# StarFive VisionFive 2 v1.3b register map
File version: 0.1
Registers are 32-bit, read-write, no defined reset value unless marked. A register's access mark holds for its fields unless they carry their own. Offsets are from the block's base; [hi:lo] are bit positions; 'fields as' and 'values as' point back to an identical list.

## starfive_jh7110_stg_syscon_0 — From starfive,jh7110-stg-syscon, peripheral generator
Base 0x10240000
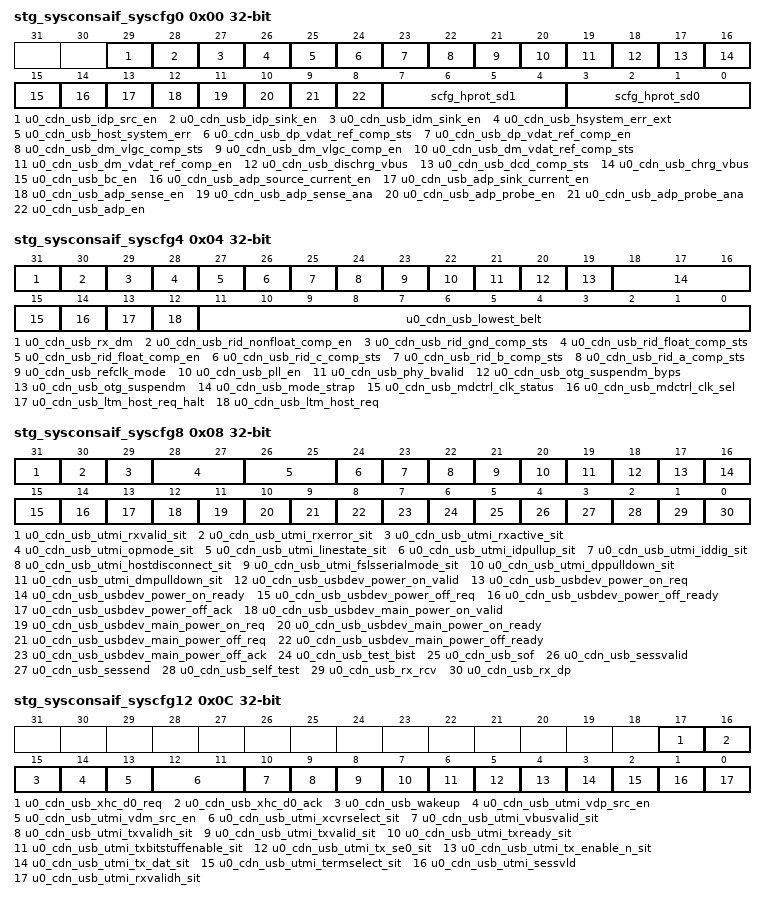
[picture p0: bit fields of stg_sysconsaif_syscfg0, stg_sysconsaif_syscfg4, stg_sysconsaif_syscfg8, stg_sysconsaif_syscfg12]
0x00 stg_sysconsaif_syscfg0
  [29] u0_cdn_usb_idp_src_en ro, [28] u0_cdn_usb_idp_sink_en ro, [27] u0_cdn_usb_idm_sink_en ro, [26] u0_cdn_usb_hsystem_err_ext ro, [25] u0_cdn_usb_host_system_err, [24] u0_cdn_usb_dp_vdat_ref_comp_sts, [23] u0_cdn_usb_dp_vdat_ref_comp_en ro, [22] u0_cdn_usb_dm_vlgc_comp_sts, [21] u0_cdn_usb_dm_vlgc_comp_en ro, [20] u0_cdn_usb_dm_vdat_ref_comp_sts, [19] u0_cdn_usb_dm_vdat_ref_comp_en ro, [18] u0_cdn_usb_dischrg_vbus, [17] u0_cdn_usb_dcd_comp_sts, [16] u0_cdn_usb_chrg_vbus, [15] u0_cdn_usb_bc_en ro, [14] u0_cdn_usb_adp_source_current_en ro, [13] u0_cdn_usb_adp_sink_current_en ro, [12] u0_cdn_usb_adp_sense_en ro, [11] u0_cdn_usb_adp_sense_ana, [10] u0_cdn_usb_adp_probe_en ro, [9] u0_cdn_usb_adp_probe_ana, [8] u0_cdn_usb_adp_en ro, [7:4] scfg_hprot_sd1, [3:0] scfg_hprot_sd0
0x04 stg_sysconsaif_syscfg4
  [31] u0_cdn_usb_rx_dm ro
  [30] u0_cdn_usb_rid_nonfloat_comp_en ro
  [29] u0_cdn_usb_rid_gnd_comp_sts
  [28] u0_cdn_usb_rid_float_comp_sts
  [27] u0_cdn_usb_rid_float_comp_en ro
  [26] u0_cdn_usb_rid_c_comp_sts
  [25] u0_cdn_usb_rid_b_comp_sts
  [24] u0_cdn_usb_rid_a_comp_sts
  [23] u0_cdn_usb_refclk_mode
  [22] u0_cdn_usb_pll_en
  [21] u0_cdn_usb_phy_bvalid ro
  [20] u0_cdn_usb_otg_suspendm_byps
  [19] u0_cdn_usb_otg_suspendm
  [18:16] u0_cdn_usb_mode_strap — Can onlly be changed when pwrup_rst_n is low
  [15] u0_cdn_usb_mdctrl_clk_status ro
  [14] u0_cdn_usb_mdctrl_clk_sel
  [13] u0_cdn_usb_ltm_host_req_halt — LTM interface to software
  [12] u0_cdn_usb_ltm_host_req ro — LTM interface to software
  [11:0] u0_cdn_usb_lowest_belt ro — LTM interface to software
0x08 stg_sysconsaif_syscfg8
  [31] u0_cdn_usb_utmi_rxvalid_sit ro
  [30] u0_cdn_usb_utmi_rxerror_sit ro
  [29] u0_cdn_usb_utmi_rxactive_sit ro
  [28:27] u0_cdn_usb_utmi_opmode_sit
  [26:25] u0_cdn_usb_utmi_linestate_sit ro
  [24] u0_cdn_usb_utmi_idpullup_sit
  [23] u0_cdn_usb_utmi_iddig_sit ro
  [22] u0_cdn_usb_utmi_hostdisconnect_sit ro
  [21] u0_cdn_usb_utmi_fslsserialmode_sit
  [20] u0_cdn_usb_utmi_dppulldown_sit
  [19] u0_cdn_usb_utmi_dmpulldown_sit
  [18] u0_cdn_usb_usbdev_power_on_valid
  [17] u0_cdn_usb_usbdev_power_on_req ro
  [16] u0_cdn_usb_usbdev_power_on_ready ro
  [15] u0_cdn_usb_usbdev_power_off_req
  [14] u0_cdn_usb_usbdev_power_off_ready ro
  [13] u0_cdn_usb_usbdev_power_off_ack ro
  [12] u0_cdn_usb_usbdev_main_power_on_valid
  [11] u0_cdn_usb_usbdev_main_power_on_req ro
  [10] u0_cdn_usb_usbdev_main_power_on_ready ro
  [9] u0_cdn_usb_usbdev_main_power_off_req
  [8] u0_cdn_usb_usbdev_main_power_off_ready ro
  [7] u0_cdn_usb_usbdev_main_power_off_ack ro
  [6] u0_cdn_usb_test_bist ro — For software bist_test
  [5] u0_cdn_usb_sof ro
  [4] u0_cdn_usb_sessvalid ro
  [3] u0_cdn_usb_sessend ro
  [2] u0_cdn_usb_self_test — For software bist_test
  [1] u0_cdn_usb_rx_rcv ro
  [0] u0_cdn_usb_rx_dp ro
0x0C stg_sysconsaif_syscfg12
  [17] u0_cdn_usb_xhc_d0_req, [16] u0_cdn_usb_xhc_d0_ack ro, [15] u0_cdn_usb_wakeup, [14] u0_cdn_usb_utmi_vdp_src_en ro, [13] u0_cdn_usb_utmi_vdm_src_en ro, [12:11] u0_cdn_usb_utmi_xcvrselect_sit, [10] u0_cdn_usb_utmi_vbusvalid_sit ro, [9] u0_cdn_usb_utmi_txvalidh_sit, [8] u0_cdn_usb_utmi_txvalid_sit, [7] u0_cdn_usb_utmi_txready_sit ro, [6] u0_cdn_usb_utmi_txbitstuffenable_sit, [5] u0_cdn_usb_utmi_tx_se0_sit, [4] u0_cdn_usb_utmi_tx_enable_n_sit, [3] u0_cdn_usb_utmi_tx_dat_sit, [2] u0_cdn_usb_utmi_termselect_sit, [1] u0_cdn_usb_utmi_sessvld, [0] u0_cdn_usb_utmi_rxvalidh_sit ro
0x10 stg_sysconsaif_syscfg16
  [31:0] u0_cdn_usb_xhci_debug_bus ro
0x14 stg_sysconsaif_syscfg20
  [30:0] u0_cdn_usb_xhci_debug_link_state ro
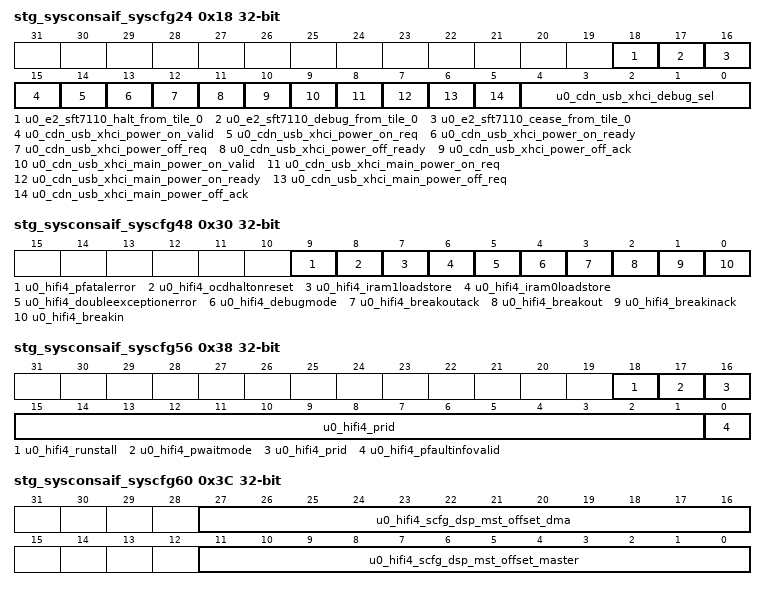
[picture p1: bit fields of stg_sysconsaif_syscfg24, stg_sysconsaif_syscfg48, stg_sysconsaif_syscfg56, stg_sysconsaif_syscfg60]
0x18 stg_sysconsaif_syscfg24
  [18] u0_e2_sft7110_halt_from_tile_0 ro, [17] u0_e2_sft7110_debug_from_tile_0 ro, [16] u0_e2_sft7110_cease_from_tile_0 ro, [15] u0_cdn_usb_xhci_power_on_valid, [14] u0_cdn_usb_xhci_power_on_req ro, [13] u0_cdn_usb_xhci_power_on_ready ro, [12] u0_cdn_usb_xhci_power_off_req, [11] u0_cdn_usb_xhci_power_off_ready ro, [10] u0_cdn_usb_xhci_power_off_ack ro, [9] u0_cdn_usb_xhci_main_power_on_valid, [8] u0_cdn_usb_xhci_main_power_on_req ro, [7] u0_cdn_usb_xhci_main_power_on_ready, [6] u0_cdn_usb_xhci_main_power_off_req ro, [5] u0_cdn_usb_xhci_main_power_off_ack ro, [4:0] u0_cdn_usb_xhci_debug_sel
0x1C stg_sysconsaif_syscfg28
  [31:0] u0_e2_sft7110_nmi_0_rnmi_exception_vector
0x20 stg_sysconsaif_syscfg32
  [31:0] u0_e2_sft7110_nmi_0_rnmi_interrupt_vector
0x24 stg_sysconsaif_syscfg36
  [31:0] u0_e2_sft7110_reset_vector_0
0x28 stg_sysconsaif_syscfg40
  [0] u0_e2_sft7110_wfi_from_tile_0 ro
0x2C stg_sysconsaif_syscfg44
  [31:0] u0_hifi4_altresetvec — Reset Vector Address
0x30 stg_sysconsaif_syscfg48
  [9] u0_hifi4_pfatalerror ro — Fault Handling Signals
  [8] u0_hifi4_ocdhaltonreset — Debug signal
  [7] u0_hifi4_iram1loadstore ro — Indicates that iram1 works
  [6] u0_hifi4_iram0loadstore ro — Indicates that iram0 works
  [5] u0_hifi4_doubleexceptionerror ro — Fault Handling Signals
  [4] u0_hifi4_debugmode ro — Debug signal
  [3] u0_hifi4_breakoutack — Debug signal
  [2] u0_hifi4_breakout ro — Debug signal
  [1] u0_hifi4_breakinack ro — Debug signal
  [0] u0_hifi4_breakin — Debug signal
0x34 stg_sysconsaif_syscfg52
  [31:0] u0_hifi4_pfaultinfo ro — Fault Handling Signals
0x38 stg_sysconsaif_syscfg56
  [18] u0_hifi4_runstall — Run Stall
  [17] u0_hifi4_pwaitmode ro — Wait Mode
  [16:1] u0_hifi4_prid — Module ID
  [0] u0_hifi4_pfaultinfovalid ro — Fault Handling Signals
0x3C stg_sysconsaif_syscfg60
  [27:16] u0_hifi4_scfg_dsp_mst_offset_dma — Indicates the DMA port remap address
  [11:0] u0_hifi4_scfg_dsp_mst_offset_master — Indicates that master port remap address
0x40 stg_sysconsaif_syscfg64
  [31:0] u0_hifi4_scfg_dsp_slv_offset — The value indicates the slave port remap address
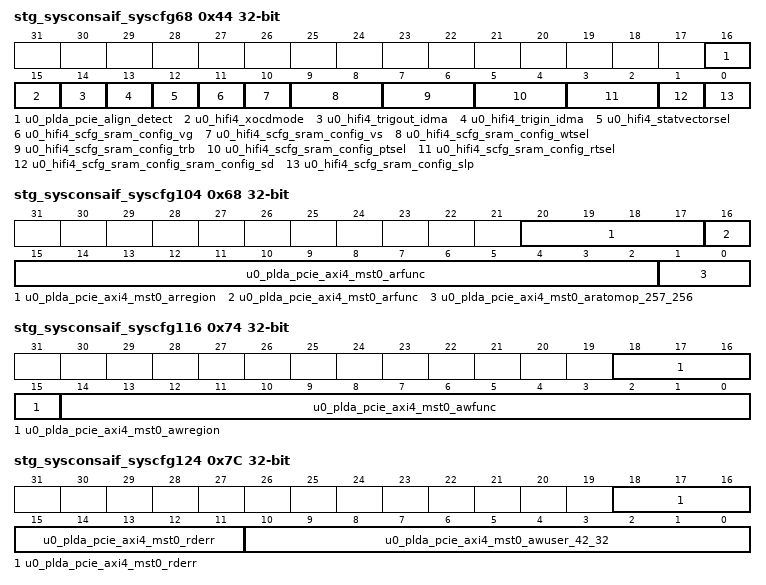
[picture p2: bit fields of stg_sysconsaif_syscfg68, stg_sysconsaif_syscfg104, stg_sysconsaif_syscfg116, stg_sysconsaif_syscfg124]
0x44 stg_sysconsaif_syscfg68
  [16] u0_plda_pcie_align_detect ro
  [15] u0_hifi4_xocdmode ro — Debug signal
  [14] u0_hifi4_trigout_idma ro — DMA port trigger
  [13] u0_hifi4_trigin_idma — DMA port trigger
  [12] u0_hifi4_statvectorsel — When the value is 1, it indicates that the AltResetVec is valid
  [11] u0_hifi4_scfg_sram_config_vg — SRAM/ROM configuration. VG: timing setting for debug purpose, default is 1'b1.
  [10] u0_hifi4_scfg_sram_config_vs — SRAM/ROM configuration. VS: timing setting for debug purpose, default is 1'b1.
  [9:8] u0_hifi4_scfg_sram_config_wtsel — SRAM/ROM configuration. WTSEL: timing setting for debug purpose, default is 2'b01.
  [7:6] u0_hifi4_scfg_sram_config_trb — SRAM/ROM configuration. TRB: timing setting for debug purpose, default is 2'b01.
  [5:4] u0_hifi4_scfg_sram_config_ptsel — SRAM/ROM configuration. PTSEL: timing setting for debug purpose, default is 2'b01.
  [3:2] u0_hifi4_scfg_sram_config_rtsel — SRAM/ROM configuration. RTSEL: timing setting for debug purpose, default is 2'b01.
  [1] u0_hifi4_scfg_sram_config_sram_config_sd — SRAM/ROM configuration. SD: shutdown enable, high active, default is low.
  [0] u0_hifi4_scfg_sram_config_slp — SRAM/ROM configuration. SLP: sleep enable, high active, default is low.
0x48 stg_sysconsaif_syscfg72
  [31:0] u0_plda_pcie_axi4_mst0_aratomop_31_0 ro
0x4C stg_sysconsaif_syscfg76
  [31:0] u0_plda_pcie_axi4_mst0_aratomop_63_32 ro
0x50 stg_sysconsaif_syscfg80
  [31:0] u0_plda_pcie_axi4_mst0_aratomop_95_64 ro
0x54 stg_sysconsaif_syscfg84
  [31:0] u0_plda_pcie_axi4_mst0_aratomop_127_96 ro
0x58 stg_sysconsaif_syscfg88
  [31:0] u0_plda_pcie_axi4_mst0_aratomop_159_128 ro
0x5C stg_sysconsaif_syscfg92
  [31:0] u0_plda_pcie_axi4_mst0_aratomop_191_160 ro
0x60 stg_sysconsaif_syscfg96
  [31:0] u0_plda_pcie_axi4_mst0_aratomop_223_192 ro
0x64 stg_sysconsaif_syscfg100
  [31:0] u0_plda_pcie_axi4_mst0_aratomop_255_224 ro
0x68 stg_sysconsaif_syscfg104
  [20:17] u0_plda_pcie_axi4_mst0_arregion ro, [16:2] u0_plda_pcie_axi4_mst0_arfunc ro, [1:0] u0_plda_pcie_axi4_mst0_aratomop_257_256 ro
0x6C stg_sysconsaif_syscfg108
  [31:0] u0_plda_pcie_axi4_mst0_aruser_31_0 ro
0x70 stg_sysconsaif_syscfg112
  [31:0] u0_plda_pcie_axi4_mst0_aruser_63_32 ro
0x74 stg_sysconsaif_syscfg116
  [18:15] u0_plda_pcie_axi4_mst0_awregion ro, [14:0] u0_plda_pcie_axi4_mst0_awfunc ro
0x78 stg_sysconsaif_syscfg120
  [31:0] u0_plda_pcie_axi4_mst0_a2user_31_0 ro
0x7C stg_sysconsaif_syscfg124
  [18:11] u0_plda_pcie_axi4_mst0_rderr, [10:0] u0_plda_pcie_axi4_mst0_awuser_42_32 ro
0x80 stg_sysconsaif_syscfg128
  [31:0] u0_plda_pcie_axi4_mst0_ruser
0x84 stg_sysconsaif_syscfg132
  [7:0] u0_plda_pcie_axi4_mst0_wderr ro
0x88 stg_sysconsaif_syscfg136
  [31:0] u0_plda_pcie_axi4_slv0_aratomop_31_0
0x8C stg_sysconsaif_syscfg140
  [31:0] u0_plda_pcie_axi4_slv0_aratomop_63_32
0x90 stg_sysconsaif_syscfg144
  [31:0] u0_plda_pcie_axi4_slv0_aratomop_95_64
0x94 stg_sysconsaif_syscfg148
  [31:0] u0_plda_pcie_axi4_slv0_aratomop_127_96
0x98 stg_sysconsaif_syscfg152
  [31:0] u0_plda_pcie_axi4_slv0_aratomop_159_128
0x9C stg_sysconsaif_syscfg156
  [31:0] u0_plda_pcie_axi4_slv0_aratomop_191_160
0xA0 stg_sysconsaif_syscfg160
  [31:0] u0_plda_pcie_axi4_slv0_aratomop_223_192
0xA4 stg_sysconsaif_syscfg164
  [31:0] u0_plda_pcie_axi4_slv0_aratomop_255_224
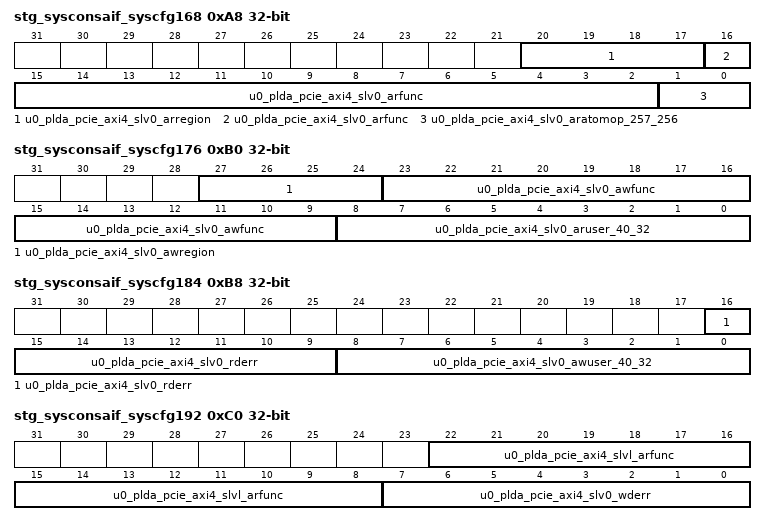
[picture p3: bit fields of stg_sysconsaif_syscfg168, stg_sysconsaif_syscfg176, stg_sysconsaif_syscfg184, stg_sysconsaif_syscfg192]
0xA8 stg_sysconsaif_syscfg168
  [20:17] u0_plda_pcie_axi4_slv0_arregion, [16:2] u0_plda_pcie_axi4_slv0_arfunc, [1:0] u0_plda_pcie_axi4_slv0_aratomop_257_256
0xAC stg_sysconsaif_syscfg172
  [31:0] u0_plda_pcie_axi4_slv0_aruser_31_0
0xB0 stg_sysconsaif_syscfg176
  [27:24] u0_plda_pcie_axi4_slv0_awregion, [23:9] u0_plda_pcie_axi4_slv0_awfunc, [8:0] u0_plda_pcie_axi4_slv0_aruser_40_32
0xB4 stg_sysconsaif_syscfg180
  [31:0] u0_plda_pcie_axi4_slv0_awuser_31_0
0xB8 stg_sysconsaif_syscfg184
  [16:9] u0_plda_pcie_axi4_slv0_rderr ro, [8:0] u0_plda_pcie_axi4_slv0_awuser_40_32
0xBC stg_sysconsaif_syscfg188
  [31:0] u0_plda_pcie_axi4_slv0_ruser ro
0xC0 stg_sysconsaif_syscfg192
  [22:8] u0_plda_pcie_axi4_slvl_arfunc ro, [7:0] u0_plda_pcie_axi4_slv0_wderr
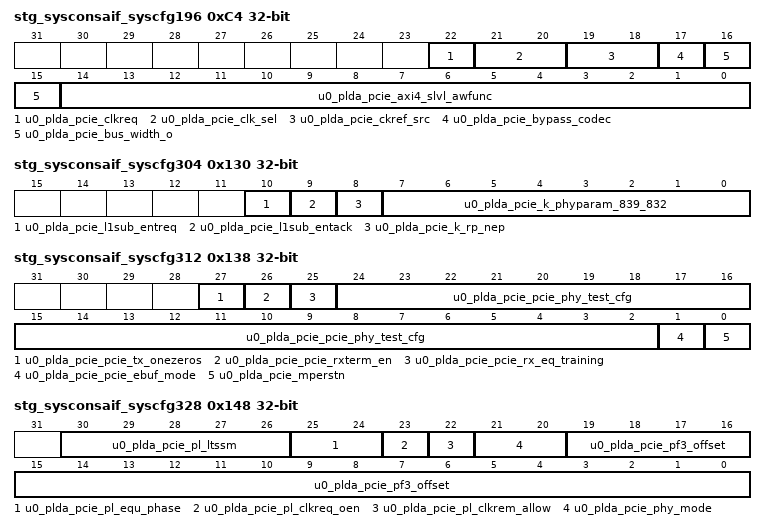
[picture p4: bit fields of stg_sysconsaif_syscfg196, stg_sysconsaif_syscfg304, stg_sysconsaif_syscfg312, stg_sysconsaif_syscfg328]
0xC4 stg_sysconsaif_syscfg196
  [22] u0_plda_pcie_clkreq, [21:20] u0_plda_pcie_clk_sel, [19:18] u0_plda_pcie_ckref_src, [17] u0_plda_pcie_bypass_codec, [16:15] u0_plda_pcie_bus_width_o ro, [14:0] u0_plda_pcie_axi4_slvl_awfunc
0xC8 stg_sysconsaif_syscfg200
  [31:0] u0_plda_pcie_k_phyparam_31_0
0xCC stg_sysconsaif_syscfg204
  [31:0] u0_plda_pcie_k_phyparam_63_32
0xD0 stg_sysconsaif_syscfg208
  [31:0] u0_plda_pcie_k_phyparam_95_64
0xD4 stg_sysconsaif_syscfg212
  [31:0] u0_plda_pcie_k_phyparam_127_96
0xD8 stg_sysconsaif_syscfg216
  [31:0] u0_plda_pcie_k_phyparam_159_128
0xDC stg_sysconsaif_syscfg220
  [31:0] u0_plda_pcie_k_phyparam_191_160
0xE0 stg_sysconsaif_syscfg224
  [31:0] u0_plda_pcie_k_phyparam_223_192
0xE4 stg_sysconsaif_syscfg228
  [31:0] u0_plda_pcie_k_phyparam_255_224
0xE8 stg_sysconsaif_syscfg232
  [31:0] u0_plda_pcie_k_phyparam_287_256
0xEC stg_sysconsaif_syscfg236
  [31:0] u0_plda_pcie_k_phyparam_319_288
0xF0 stg_sysconsaif_syscfg240
  [31:0] u0_plda_pcie_k_phyparam_351_320
0xF4 stg_sysconsaif_syscfg244
  [31:0] u0_plda_pcie_k_phyparam_383_352
0xF8 stg_sysconsaif_syscfg248
  [31:0] u0_plda_pcie_k_phyparam_415_384
0xFC stg_sysconsaif_syscfg252
  [31:0] u0_plda_pcie_k_phyparam_447_416
0x100 stg_sysconsaif_syscfg256
  [31:0] u0_plda_pcie_k_phyparam_479_448
0x104 stg_sysconsaif_syscfg260
  [31:0] u0_plda_pcie_k_phyparam_511_480
0x108 stg_sysconsaif_syscfg264
  [31:0] u0_plda_pcie_k_phyparam_543_512
0x10C stg_sysconsaif_syscfg268
  [31:0] u0_plda_pcie_k_phyparam_575_544
0x110 stg_sysconsaif_syscfg272
  [31:0] u0_plda_pcie_k_phyparam_607_576
0x114 stg_sysconsaif_syscfg276
  [31:0] u0_plda_pcie_k_phyparam_639_608
0x118 stg_sysconsaif_syscfg280
  [31:0] u0_plda_pcie_k_phyparam_671_640
0x11C stg_sysconsaif_syscfg284
  [31:0] u0_plda_pcie_k_phyparam_703_672
0x120 stg_sysconsaif_syscfg288
  [31:0] u0_plda_pcie_k_phyparam_735_704
0x124 stg_sysconsaif_syscfg292
  [31:0] u0_plda_pcie_k_phyparam_767_736
0x128 stg_sysconsaif_syscfg296
  [31:0] u0_plda_pcie_k_phyparam_799_768
0x12C stg_sysconsaif_syscfg300
  [31:0] u0_plda_pcie_k_phyparam_831_800
0x130 stg_sysconsaif_syscfg304
  [10] u0_plda_pcie_l1sub_entreq, [9] u0_plda_pcie_l1sub_entack ro, [8] u0_plda_pcie_k_rp_nep, [7:0] u0_plda_pcie_k_phyparam_839_832
0x134 stg_sysconsaif_syscfg308
  [31:0] u0_plda_pcie_local_interrupt_in
0x138 stg_sysconsaif_syscfg312
  [27] u0_plda_pcie_pcie_tx_onezeros, [26] u0_plda_pcie_pcie_rxterm_en, [25] u0_plda_pcie_pcie_rx_eq_training, [24:2] u0_plda_pcie_pcie_phy_test_cfg, [1] u0_plda_pcie_pcie_ebuf_mode, [0] u0_plda_pcie_mperstn
0x13C stg_sysconsaif_syscfg316
  [19:0] u0_plda_pcie_pf0_offset
0x140 stg_sysconsaif_syscfg320
  [19:0] u0_plda_pcie_pf1_offset
0x144 stg_sysconsaif_syscfg324
  [19:0] u0_plda_pcie_pf2_offset
0x148 stg_sysconsaif_syscfg328
  [30:26] u0_plda_pcie_pl_ltssm ro, [25:24] u0_plda_pcie_pl_equ_phase ro, [23] u0_plda_pcie_pl_clkreq_oen ro, [22] u0_plda_pcie_pl_clkrem_allow, [21:20] u0_plda_pcie_phy_mode, [19:0] u0_plda_pcie_pf3_offset
0x14C stg_sysconsaif_syscfg332
  [4:0] u0_plda_pcie_pl_pclk_rate ro
0x150 stg_sysconsaif_syscfg336
  [31:0] u0_plda_pcie_pl_sideband_in_31_0 ro
0x154 stg_sysconsaif_syscfg340
  [31:0] u0_plda_pcie_pl_sideband_in_63_32 ro
0x158 stg_sysconsaif_syscfg344
  [31:0] u0_plda_pcie_pl_sideband_out_31_0 ro
0x15C stg_sysconsaif_syscfg348
  [31:0] u0_plda_pcie_pl_sideband_out_63_32 ro
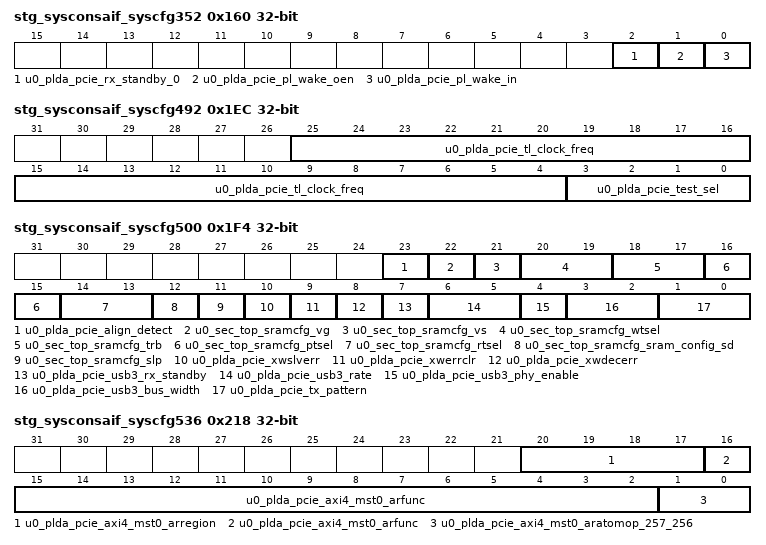
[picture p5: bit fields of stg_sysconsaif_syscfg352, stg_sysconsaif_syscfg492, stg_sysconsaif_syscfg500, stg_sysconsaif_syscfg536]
0x160 stg_sysconsaif_syscfg352
  [2] u0_plda_pcie_rx_standby_0 ro, [1] u0_plda_pcie_pl_wake_oen ro, [0] u0_plda_pcie_pl_wake_in
0x164 stg_sysconsaif_syscfg356
  [31:0] u0_plda_pcie_test_in_31_0
0x168 stg_sysconsaif_syscfg360
  [31:0] u0_plda_pcie_test_in_63_32
0x16C stg_sysconsaif_syscfg364
  [31:0] u0_plda_pcie_test_out_bridge_31_0 ro
0x170 stg_sysconsaif_syscfg368
  [31:0] u0_plda_pcie_test_out_bridge_63_32 ro
0x174 stg_sysconsaif_syscfg372
  [31:0] u0_plda_pcie_test_out_bridge_95_64 ro
0x178 stg_sysconsaif_syscfg376
  [31:0] u0_plda_pcie_test_out_bridge_127_96 ro
0x17C stg_sysconsaif_syscfg380
  [31:0] u0_plda_pcie_test_out_bridge_159_128 ro
0x180 stg_sysconsaif_syscfg384
  [31:0] u0_plda_pcie_test_out_bridge_191_160 ro
0x184 stg_sysconsaif_syscfg388
  [31:0] u0_plda_pcie_test_out_bridge_223_192 ro
0x188 stg_sysconsaif_syscfg392
  [31:0] u0_plda_pcie_test_out_bridge_255_224 ro
0x18C stg_sysconsaif_syscfg396
  [31:0] u0_plda_pcie_test_out_bridge_287_256 ro
0x190 stg_sysconsaif_syscfg400
  [31:0] u0_plda_pcie_test_out_bridge_319_288 ro
0x194 stg_sysconsaif_syscfg404
  [31:0] u0_plda_pcie_test_out_bridge_351_320 ro
0x198 stg_sysconsaif_syscfg408
  [31:0] u0_plda_pcie_test_out_bridge_383_352 ro
0x19C stg_sysconsaif_syscfg412
  [31:0] u0_plda_pcie_test_out_bridge_415_384 ro
0x1A0 stg_sysconsaif_syscfg416
  [31:0] u0_plda_pcie_test_out_bridge_447_416 ro
0x1A4 stg_sysconsaif_syscfg420
  [31:0] u0_plda_pcie_test_out_bridge_479_448 ro
0x1A8 stg_sysconsaif_syscfg424
  [31:0] u0_plda_pcie_test_out_bridge_511_480 ro
0x1AC stg_sysconsaif_syscfg428
  [31:0] u0_plda_pcie_test_out_pcie_31_0 ro
0x1B0 stg_sysconsaif_syscfg432
  [31:0] u0_plda_pcie_test_out_pcie_63_32 ro
0x1B4 stg_sysconsaif_syscfg436
  [31:0] u0_plda_pcie_test_out_pcie_95_64 ro
0x1B8 stg_sysconsaif_syscfg440
  [31:0] u0_plda_pcie_test_out_pcie_127_96 ro
0x1BC stg_sysconsaif_syscfg444
  [31:0] u0_plda_pcie_test_out_pcie_159_128 ro
0x1C0 stg_sysconsaif_syscfg448
  [31:0] u0_plda_pcie_test_out_pcie_191_160 ro
0x1C4 stg_sysconsaif_syscfg452
  [31:0] u0_plda_pcie_test_out_pcie_223_192 ro
0x1C8 stg_sysconsaif_syscfg456
  [31:0] u0_plda_pcie_test_out_pcie_255_224 ro
0x1CC stg_sysconsaif_syscfg460
  [31:0] u0_plda_pcie_test_out_pcie_287_256 ro
0x1D0 stg_sysconsaif_syscfg464
  [31:0] u0_plda_pcie_test_out_pcie_319_288 ro
0x1D4 stg_sysconsaif_syscfg468
  [31:0] u0_plda_pcie_test_out_pcie_351_320 ro
0x1D8 stg_sysconsaif_syscfg472
  [31:0] u0_plda_pcie_test_out_pcie_383_352 ro
0x1DC stg_sysconsaif_syscfg476
  [31:0] u0_plda_pcie_test_out_pcie_415_384 ro
0x1E0 stg_sysconsaif_syscfg480
  [31:0] u0_plda_pcie_test_out_pcie_447_416 ro
0x1E4 stg_sysconsaif_syscfg484
  [31:0] u0_plda_pcie_test_out_pcie_479_448 ro
0x1E8 stg_sysconsaif_syscfg488
  [31:0] u0_plda_pcie_test_out_pcie_511_480 ro
0x1EC stg_sysconsaif_syscfg492
  [25:4] u0_plda_pcie_tl_clock_freq, [3:0] u0_plda_pcie_test_sel
0x1F4 stg_sysconsaif_syscfg500
  [23] u0_plda_pcie_align_detect ro
  [22] u0_sec_top_sramcfg_vg — SRAM/ROM configuration. VG: timing setting for debug purpose, default is 1'b1.
  [21] u0_sec_top_sramcfg_vs — SRAM/ROM configuration. VS: timing setting for debug purpose, default is 1'b1.
  [20:19] u0_sec_top_sramcfg_wtsel — SRAM/ROM configuration. WTSEL: timing setting for debug purpose, default is 2'b01.
  [18:17] u0_sec_top_sramcfg_trb — SRAM/ROM configuration. TRB: timing setting for debug purpose, default is 2'b01.
  [16:15] u0_sec_top_sramcfg_ptsel — SRAM/ROM configuration. PTSEL: timing setting for debug purpose, default is 2'b01.
  [14:13] u0_sec_top_sramcfg_rtsel — SRAM/ROM configuration. RTSEL: timing setting for debug purpose, default is 2'b01.
  [12] u0_sec_top_sramcfg_sram_config_sd — SRAM/ROM configuration. SD: shutdown enable, high active, default is low.
  [11] u0_sec_top_sramcfg_slp — SRAM/ROM configuration. SLP: sleep enable, high active, default is low.
  [10] u0_plda_pcie_xwslverr ro
  [9] u0_plda_pcie_xwerrclr
  [8] u0_plda_pcie_xwdecerr ro
  [7] u0_plda_pcie_usb3_rx_standby
  [6:5] u0_plda_pcie_usb3_rate
  [4] u0_plda_pcie_usb3_phy_enable
  [3:2] u0_plda_pcie_usb3_bus_width
  [1:0] u0_plda_pcie_tx_pattern
0x1F8 stg_sysconsaif_syscfg504
  [31:0] u0_plda_pcie_axi4_mst0_aratomop_31_0 ro
0x1FC stg_sysconsaif_syscfg508
  [31:0] u0_plda_pcie_axi4_mst0_aratomop_63_32 ro
0x200 stg_sysconsaif_syscfg512
  [31:0] u0_plda_pcie_axi4_mst0_aratomop_95_64 ro
0x204 stg_sysconsaif_syscfg516
  [31:0] u0_plda_pcie_axi4_mst0_aratomop_127_96 ro
0x208 stg_sysconsaif_syscfg520
  [31:0] u0_plda_pcie_axi4_mst0_aratomop_159_128 ro
0x20C stg_sysconsaif_syscfg524
  [31:0] u0_plda_pcie_axi4_mst0_aratomop_191_160 ro
0x210 stg_sysconsaif_syscfg528
  [31:0] u0_plda_pcie_axi4_mst0_aratomop_223_192 ro
0x214 stg_sysconsaif_syscfg532
  [31:0] u0_plda_pcie_axi4_mst0_aratomop_255_224 ro
0x218 stg_sysconsaif_syscfg536
  fields as stg_sysconsaif_syscfg104
0x21C stg_sysconsaif_syscfg540
  [31:0] u1_plda_pcie_axi4_mst0_aruser_31_0 ro
0x220 stg_sysconsaif_syscfg544
  [20:0] u1_plda_pcie_axi4_mst0_aruser_52_32 ro
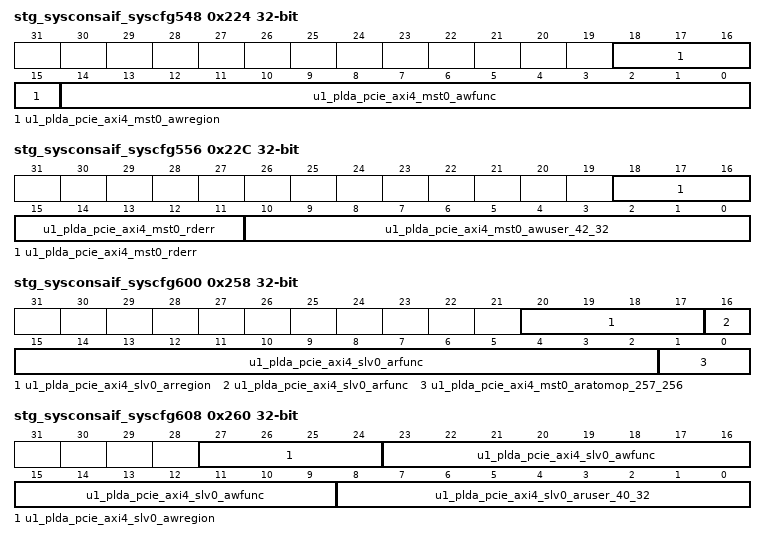
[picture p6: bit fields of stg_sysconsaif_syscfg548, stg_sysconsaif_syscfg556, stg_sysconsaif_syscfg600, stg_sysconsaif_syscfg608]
0x224 stg_sysconsaif_syscfg548
  [18:15] u1_plda_pcie_axi4_mst0_awregion ro, [14:0] u1_plda_pcie_axi4_mst0_awfunc ro
0x228 stg_sysconsaif_syscfg552
  [31:0] u1_plda_pcie_axi4_mst0_awuser_31_0 ro
0x22C stg_sysconsaif_syscfg556
  [18:11] u1_plda_pcie_axi4_mst0_rderr, [10:0] u1_plda_pcie_axi4_mst0_awuser_42_32 ro
0x230 stg_sysconsaif_syscfg560
  [31:0] u1_plda_pcie_axi4_mst0_ruser
0x234 stg_sysconsaif_syscfg564
  [7:0] u1_plda_pcie_axi4_mst0_wderr ro
0x238 stg_sysconsaif_syscfg568
  [31:0] u1_plda_pcie_axi4_slv0_aratomop_31_0
0x23C stg_sysconsaif_syscfg572
  [31:0] u1_plda_pcie_axi4_slv0_aratomop_63_32
0x240 stg_sysconsaif_syscfg576
  [31:0] u1_plda_pcie_axi4_slv0_aratomop_95_64
0x244 stg_sysconsaif_syscfg580
  [31:0] u1_plda_pcie_axi4_slv0_aratomop_127_96
0x248 stg_sysconsaif_syscfg584
  [31:0] u1_plda_pcie_axi4_slv0_aratomop_159_128
0x24C stg_sysconsaif_syscfg588
  [31:0] u1_plda_pcie_axi4_slv0_aratomop_191_160
0x250 stg_sysconsaif_syscfg592
  [31:0] u1_plda_pcie_axi4_slv0_aratomop_223_192
0x254 stg_sysconsaif_syscfg596
  [31:0] u1_plda_pcie_axi4_slv0_aratomop_255_224
0x258 stg_sysconsaif_syscfg600
  [20:17] u1_plda_pcie_axi4_slv0_arregion, [16:2] u1_plda_pcie_axi4_slv0_arfunc, [1:0] u1_plda_pcie_axi4_mst0_aratomop_257_256
0x25C stg_sysconsaif_syscfg604
  [31:0] u1_plda_pcie_axi4_slv0_aruser_31_0
0x260 stg_sysconsaif_syscfg608
  [27:24] u1_plda_pcie_axi4_slv0_awregion, [23:9] u1_plda_pcie_axi4_slv0_awfunc, [8:0] u1_plda_pcie_axi4_slv0_aruser_40_32
0x264 stg_sysconsaif_syscfg612
  [31:0] u1_plda_pcie_axi4_slv0_awuser_31_0
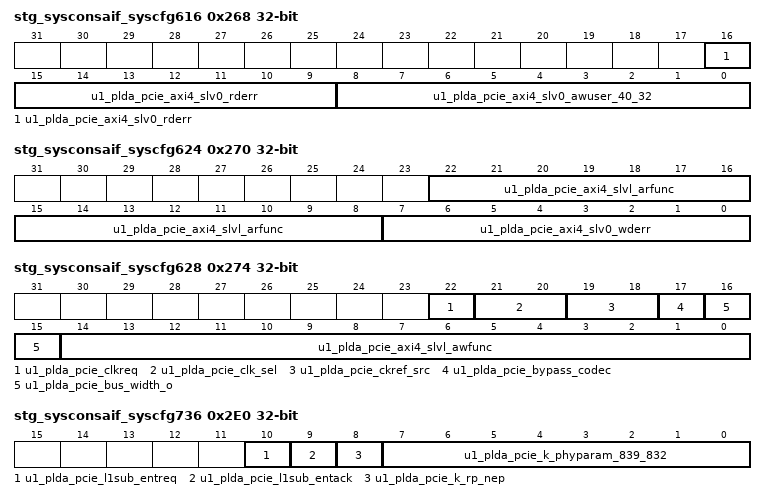
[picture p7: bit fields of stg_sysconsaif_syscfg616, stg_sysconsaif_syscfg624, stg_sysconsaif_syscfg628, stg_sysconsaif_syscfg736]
0x268 stg_sysconsaif_syscfg616
  [16:9] u1_plda_pcie_axi4_slv0_rderr ro, [8:0] u1_plda_pcie_axi4_slv0_awuser_40_32
0x26C stg_sysconsaif_syscfg620
  [31:0] u1_plda_pcie_axi4_slv0_ruser ro
0x270 stg_sysconsaif_syscfg624
  [22:8] u1_plda_pcie_axi4_slvl_arfunc, [7:0] u1_plda_pcie_axi4_slv0_wderr
0x274 stg_sysconsaif_syscfg628
  [22] u1_plda_pcie_clkreq, [21:20] u1_plda_pcie_clk_sel, [19:18] u1_plda_pcie_ckref_src, [17] u1_plda_pcie_bypass_codec, [16:15] u1_plda_pcie_bus_width_o ro, [14:0] u1_plda_pcie_axi4_slvl_awfunc
0x278 stg_sysconsaif_syscfg632
  [31:0] u1_plda_pcie_k_phyparam_31_0
0x27C stg_sysconsaif_syscfg636
  [31:0] u1_plda_pcie_k_phyparam_63_32
0x280 stg_sysconsaif_syscfg640
  [31:0] u1_plda_pcie_k_phyparam_95_64
0x284 stg_sysconsaif_syscfg644
  [31:0] u1_plda_pcie_k_phyparam_127_96
0x288 stg_sysconsaif_syscfg648
  [31:0] u1_plda_pcie_k_phyparam_159_128
0x28C stg_sysconsaif_syscfg652
  [31:0] u1_plda_pcie_k_phyparam_191_160
0x290 stg_sysconsaif_syscfg656
  [31:0] u1_plda_pcie_k_phyparam_223_192
0x294 stg_sysconsaif_syscfg660
  [31:0] u1_plda_pcie_k_phyparam_255_224
0x298 stg_sysconsaif_syscfg664
  [31:0] u1_plda_pcie_k_phyparam_287_256
0x29C stg_sysconsaif_syscfg668
  [31:0] u1_plda_pcie_k_phyparam_319_288
0x2A0 stg_sysconsaif_syscfg672
  [31:0] u1_plda_pcie_k_phyparam_351_320
0x2A4 stg_sysconsaif_syscfg676
  [31:0] u1_plda_pcie_k_phyparam_383_352
0x2A8 stg_sysconsaif_syscfg680
  [31:0] u1_plda_pcie_k_phyparam_415_384
0x2AC stg_sysconsaif_syscfg684
  [31:0] u1_plda_pcie_k_phyparam_447_416
0x2B0 stg_sysconsaif_syscfg688
  [31:0] u1_plda_pcie_k_phyparam_479_448
0x2B4 stg_sysconsaif_syscfg692
  [31:0] u1_plda_pcie_k_phyparam_511_480
0x2B8 stg_sysconsaif_syscfg696
  [31:0] u1_plda_pcie_k_phyparam_543_512
0x2BC stg_sysconsaif_syscfg700
  [31:0] u1_plda_pcie_k_phyparam_575_544
0x2C0 stg_sysconsaif_syscfg704
  [31:0] u1_plda_pcie_k_phyparam_607_576
0x2C4 stg_sysconsaif_syscfg708
  [31:0] u1_plda_pcie_k_phyparam_639_608
0x2C8 stg_sysconsaif_syscfg712
  [31:0] u1_plda_pcie_k_phyparam_671_640
0x2CC stg_sysconsaif_syscfg716
  [31:0] u1_plda_pcie_k_phyparam_703_672
0x2D0 stg_sysconsaif_syscfg720
  [31:0] u1_plda_pcie_k_phyparam_735_704
0x2D4 stg_sysconsaif_syscfg724
  [31:0] u1_plda_pcie_k_phyparam_767_736
0x2D8 stg_sysconsaif_syscfg728
  [31:0] u1_plda_pcie_k_phyparam_799_768
0x2DC stg_sysconsaif_syscfg732
  [31:0] u1_plda_pcie_k_phyparam_831_800
0x2E0 stg_sysconsaif_syscfg736
  [10] u1_plda_pcie_l1sub_entreq, [9] u1_plda_pcie_l1sub_entack ro, [8] u1_plda_pcie_k_rp_nep, [7:0] u1_plda_pcie_k_phyparam_839_832
0x2E4 stg_sysconsaif_syscfg740
  [31:0] u1_plda_pcie_local_interrupt_in
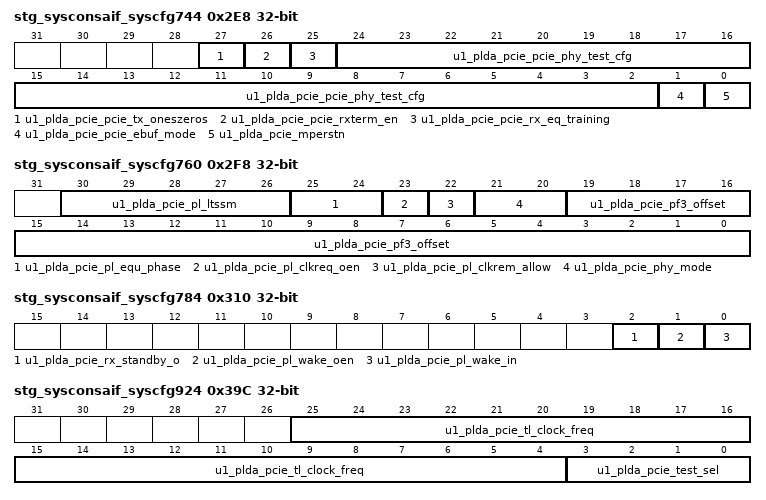
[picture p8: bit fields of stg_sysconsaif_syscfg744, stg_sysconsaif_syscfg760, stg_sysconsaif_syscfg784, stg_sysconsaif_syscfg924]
0x2E8 stg_sysconsaif_syscfg744
  [27] u1_plda_pcie_pcie_tx_oneszeros, [26] u1_plda_pcie_pcie_rxterm_en, [25] u1_plda_pcie_pcie_rx_eq_training, [24:2] u1_plda_pcie_pcie_phy_test_cfg, [1] u1_plda_pcie_pcie_ebuf_mode, [0] u1_plda_pcie_mperstn
0x2EC stg_sysconsaif_syscfg748
  [19:0] u1_plda_pcie_pf0_offset
0x2F0 stg_sysconsaif_syscfg752
  [19:0] u1_plda_pcie_pf1_offset
0x2F4 stg_sysconsaif_syscfg756
  [19:0] u1_plda_pcie_pf2_offset
0x2F8 stg_sysconsaif_syscfg760
  [30:26] u1_plda_pcie_pl_ltssm ro, [25:24] u1_plda_pcie_pl_equ_phase ro, [23] u1_plda_pcie_pl_clkreq_oen ro, [22] u1_plda_pcie_pl_clkrem_allow, [21:20] u1_plda_pcie_phy_mode, [19:0] u1_plda_pcie_pf3_offset
0x2FC stg_sysconsaif_syscfg764
  [4:0] u1_plda_pcie_pl_pclk_rate ro
0x300 stg_sysconsaif_syscfg768
  [31:0] u1_plda_pcie_pl_sideband_in_31_0
0x304 stg_sysconsaif_syscfg772
  [31:0] u1_plda_pcie_pl_sideband_in_63_32
0x308 stg_sysconsaif_syscfg776
  [31:0] u1_plda_pcie_pl_sideband_out_31_0
0x30C stg_sysconsaif_syscfg780
  [31:0] u1_plda_pcie_pl_sideband_out_63_32
0x310 stg_sysconsaif_syscfg784
  [2] u1_plda_pcie_rx_standby_o ro, [1] u1_plda_pcie_pl_wake_oen ro, [0] u1_plda_pcie_pl_wake_in
0x314 stg_sysconsaif_syscfg788
  [31:0] u1_plda_pcie_test_in_31_0
0x318 stg_sysconsaif_syscfg792
  [31:0] u1_plda_pcie_test_in_63_32
0x31C stg_sysconsaif_syscfg796
  [31:0] u1_plda_pcie_test_out_bridge_31_0
0x320 stg_sysconsaif_syscfg800
  [31:0] u1_plda_pcie_test_out_bridge_63_32
0x324 stg_sysconsaif_syscfg804
  [31:0] u1_plda_pcie_test_out_bridge_95_64
0x328 stg_sysconsaif_syscfg808
  [31:0] u1_plda_pcie_test_out_bridge_127_96
0x32C stg_sysconsaif_syscfg812
  [31:0] u1_plda_pcie_test_out_bridge_159_128
0x330 stg_sysconsaif_syscfg816
  [31:0] u1_plda_pcie_test_out_bridge_191_160
0x334 stg_sysconsaif_syscfg820
  [31:0] u1_plda_pcie_test_out_bridge_223_192
0x338 stg_sysconsaif_syscfg824
  [31:0] u1_plda_pcie_test_out_bridge_255_224
0x33C stg_sysconsaif_syscfg828
  [31:0] u1_plda_pcie_test_out_bridge_287_256
0x340 stg_sysconsaif_syscfg832
  [31:0] u1_plda_pcie_test_out_bridge_319_288
0x344 stg_sysconsaif_syscfg836
  [31:0] u1_plda_pcie_test_out_bridge_351_320
0x348 stg_sysconsaif_syscfg840
  [31:0] u1_plda_pcie_test_out_bridge_383_352
0x34C stg_sysconsaif_syscfg844
  [31:0] u1_plda_pcie_test_out_bridge_415_384
0x350 stg_sysconsaif_syscfg848
  [31:0] u1_plda_pcie_test_out_bridge_447_416
0x354 stg_sysconsaif_syscfg852
  [31:0] u1_plda_pcie_test_out_bridge_479_448
0x358 stg_sysconsaif_syscfg856
  [31:0] u1_plda_pcie_test_out_bridge_511_480
0x35C stg_sysconsaif_syscfg860
  [31:0] u1_plda_pcie_test_out_pcie_31_0 ro
0x360 stg_sysconsaif_syscfg864
  [31:0] u1_plda_pcie_test_out_pcie_63_32 ro
0x364 stg_sysconsaif_syscfg868
  [31:0] u1_plda_pcie_test_out_pcie_95_64 ro
0x368 stg_sysconsaif_syscfg872
  [31:0] u1_plda_pcie_test_out_pcie_127_96 ro
0x36C stg_sysconsaif_syscfg876
  [31:0] u1_plda_pcie_test_out_pcie_159_128 ro
0x370 stg_sysconsaif_syscfg880
  [31:0] u1_plda_pcie_test_out_pcie_191_160 ro
0x374 stg_sysconsaif_syscfg884
  [31:0] u1_plda_pcie_test_out_pcie_223_192 ro
0x378 stg_sysconsaif_syscfg888
  [31:0] u1_plda_pcie_test_out_pcie_255_224 ro
0x37C stg_sysconsaif_syscfg892
  [31:0] u1_plda_pcie_test_out_pcie_287_256 ro
0x380 stg_sysconsaif_syscfg896
  [31:0] u1_plda_pcie_test_out_pcie_319_288 ro
0x384 stg_sysconsaif_syscfg900
  [31:0] u1_plda_pcie_test_out_pcie_351_320 ro
0x388 stg_sysconsaif_syscfg904
  [31:0] u1_plda_pcie_test_out_pcie_383_352 ro
0x38C stg_sysconsaif_syscfg908
  [31:0] u1_plda_pcie_test_out_pcie_415_384 ro
0x390 stg_sysconsaif_syscfg912
  [31:0] u1_plda_pcie_test_out_pcie_447_416 ro
0x394 stg_sysconsaif_syscfg916
  [31:0] u1_plda_pcie_test_out_pcie_479_448 ro
0x398 stg_sysconsaif_syscfg920
  [31:0] u1_plda_pcie_test_out_pcie_511_480 ro
0x39C stg_sysconsaif_syscfg924
  [25:4] u1_plda_pcie_tl_clock_freq, [3:0] u1_plda_pcie_test_sel
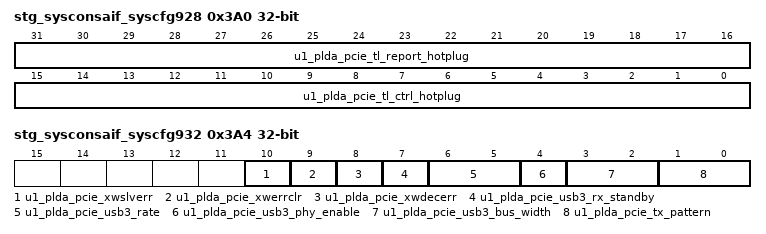
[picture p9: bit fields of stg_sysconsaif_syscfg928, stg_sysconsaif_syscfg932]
0x3A0 stg_sysconsaif_syscfg928
  [31:16] u1_plda_pcie_tl_report_hotplug, [15:0] u1_plda_pcie_tl_ctrl_hotplug ro
0x3A4 stg_sysconsaif_syscfg932
  [10] u1_plda_pcie_xwslverr ro, [9] u1_plda_pcie_xwerrclr, [8] u1_plda_pcie_xwdecerr ro, [7] u1_plda_pcie_usb3_rx_standby, [6:5] u1_plda_pcie_usb3_rate, [4] u1_plda_pcie_usb3_phy_enable, [3:2] u1_plda_pcie_usb3_bus_width, [1:0] u1_plda_pcie_tx_pattern
